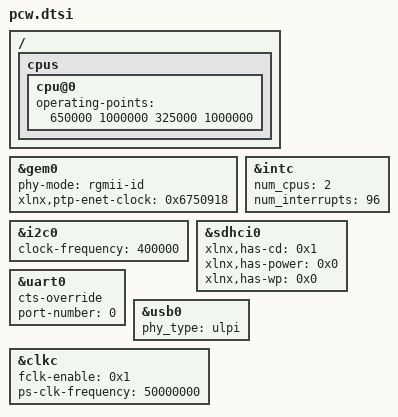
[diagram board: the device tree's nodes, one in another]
/*
 * CAUTION: This file is automatically generated by Xilinx.
 * Version:  
 * Today is: Mon May 11 19:20:20 2020
 */


/ {
	cpus {
		cpu@0 {
			operating-points = <650000 1000000 325000 1000000>;
		};
	};
};
&gem0 {
	phy-mode = "rgmii-id";
	status = "okay";
	xlnx,ptp-enet-clock = <0x6750918>;
};
&i2c0 {
	clock-frequency = <400000>;
	status = "okay";
};
&intc {
	num_cpus = <2>;
	num_interrupts = <96>;
};
&sdhci0 {
	status = "okay";
	xlnx,has-cd = <0x1>;
	xlnx,has-power = <0x0>;
	xlnx,has-wp = <0x0>;
};
&uart0 {
	cts-override ;
	device_type = "serial";
	port-number = <0>;
	status = "okay";
};
&usb0 {
	phy_type = "ulpi";
	status = "okay";
};
&clkc {
	fclk-enable = <0x1>;
	ps-clk-frequency = <50000000>;
};
